# STM32F303 register map
File version: 1.9
CPU: CM4 r1p0, little endian, MPU, FPU, 3 interrupt priority bits
Registers are 32-bit, read-write, reset 0x0 unless marked. A register's access mark holds for its fields unless they carry their own. Offsets are from the block's base; [hi:lo] are bit positions; {n}, {i} and the like mark numbered series.

## SYSCFG_COMP_OPAMP — System configuration controller _Comparator and Operational amplifier
Base 0x40010000
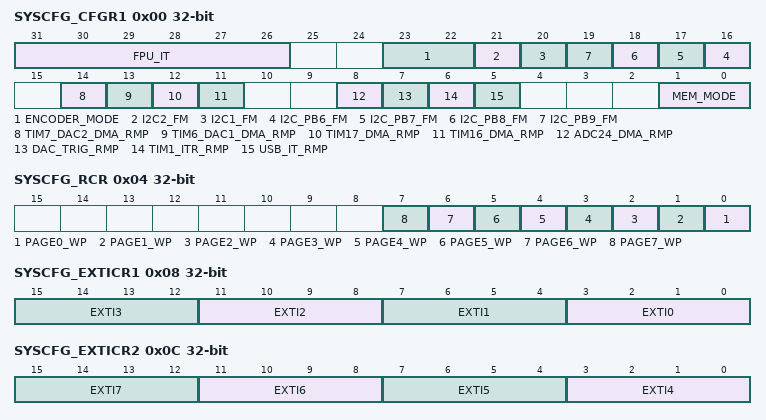
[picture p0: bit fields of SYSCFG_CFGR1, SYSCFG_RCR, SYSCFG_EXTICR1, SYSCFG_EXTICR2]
0x00 SYSCFG_CFGR1 — configuration register 1
  [31:26] FPU_IT — Interrupt enable bits from FPU
  [23:22] ENCODER_MODE
  [21] I2C2_FM — I2C2 Fast Mode Plus
  [20] I2C1_FM — I2C1 Fast Mode Plus
  [n+10] I2C_PB{n}_FM (n=6..9) — Fast Mode Plus (FM+) driving capability activation bits.
  [14] TIM7_DAC2_DMA_RMP — TIM7 and DAC2 DMA request remapping bit
  [13] TIM6_DAC1_DMA_RMP — TIM6 and DAC1 DMA request remapping bit
  [12] TIM17_DMA_RMP — TIM17 DMA request remapping bit
  [11] TIM16_DMA_RMP — TIM16 DMA request remapping bit
  [8] ADC24_DMA_RMP — ADC24 DMA remapping bit
  [7] DAC_TRIG_RMP — DAC trigger remap (when TSEL = 001)
  [6] TIM1_ITR_RMP — Timer 1 ITR3 selection
  [5] USB_IT_RMP — USB interrupt remap
  [1:0] MEM_MODE — Memory mapping selection bits
0x04 SYSCFG_RCR — CCM SRAM protection register
  [n] PAGE{n}_WP (n=0..7) — CCM SRAM page write protection bit
0x08 SYSCFG_EXTICR1 — external interrupt configuration register 1
  [4n+3:4n] EXTI{n} (n=0..3) — EXTI {n} configuration bits
0x0C SYSCFG_EXTICR2 — external interrupt configuration register 2
  [4n-13:4n-16] EXTI{n} (n=4..7) — EXTI {n} configuration bits
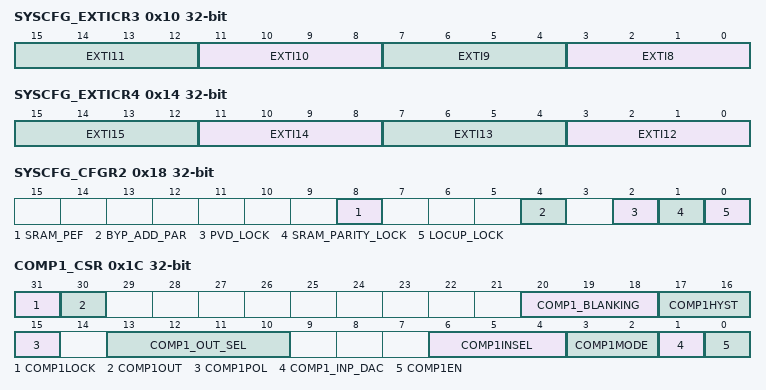
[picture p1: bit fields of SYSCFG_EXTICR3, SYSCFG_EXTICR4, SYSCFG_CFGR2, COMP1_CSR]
0x10 SYSCFG_EXTICR3 — external interrupt configuration register 3
  [4n-29:4n-32] EXTI{n} (n=8..11) — EXTI {n} configuration bits
0x14 SYSCFG_EXTICR4 — external interrupt configuration register 4
  [4n-45:4n-48] EXTI{n} (n=12..15) — EXTI {n} configuration bits
0x18 SYSCFG_CFGR2 — configuration register 2
  [8] SRAM_PEF — SRAM parity flag
  [4] BYP_ADD_PAR — Bypass address bit 29 in parity calculation
  [2] PVD_LOCK — PVD lock enable bit
  [1] SRAM_PARITY_LOCK — SRAM parity lock bit
  [0] LOCUP_LOCK — Cortex-M0 LOCKUP bit enable bit
0x1C COMP1_CSR access per field — control and status register
  [31] COMP1LOCK rw — Comparator 1 lock
  [30] COMP1OUT ro — Comparator 1 output
  [20:18] COMP1_BLANKING rw — Comparator 1 blanking source
  [17:16] COMP1HYST rw — Comparator 1 hysteresis
  [15] COMP1POL rw — Comparator 1 output polarity
  [13:10] COMP1_OUT_SEL rw — Comparator 1 output selection
  [6:4] COMP1INSEL rw — Comparator 1 inverting input selection
  [3:2] COMP1MODE rw — Comparator 1 mode
  [1] COMP1_INP_DAC rw
  [0] COMP1EN rw — Comparator 1 enable
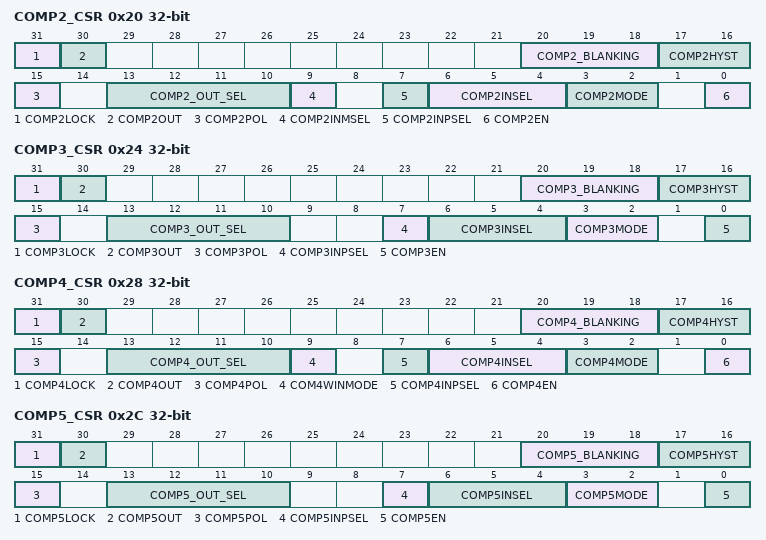
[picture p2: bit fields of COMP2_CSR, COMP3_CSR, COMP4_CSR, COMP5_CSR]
0x20 COMP2_CSR — control and status register
  [31] COMP2LOCK — Comparator 2 lock
  [30] COMP2OUT — Comparator 2 output
  [20:18] COMP2_BLANKING — Comparator 2 blanking source
  [17:16] COMP2HYST — Comparator 2 hysteresis
  [15] COMP2POL — Comparator 2 output polarity
  [13:10] COMP2_OUT_SEL — Comparator 2 output selection
  [9] COMP2INMSEL — Comparator 1inverting input selection
  [7] COMP2INPSEL — Comparator 2 non inverted input selection
  [6:4] COMP2INSEL — Comparator 2 inverting input selection
  [3:2] COMP2MODE — Comparator 2 mode
  [0] COMP2EN — Comparator 2 enable
0x24 COMP3_CSR access per field — control and status register
  [31] COMP3LOCK rw — Comparator 3 lock
  [30] COMP3OUT ro — Comparator 3 output
  [20:18] COMP3_BLANKING rw — Comparator 3 blanking source
  [17:16] COMP3HYST rw — Comparator 3 hysteresis
  [15] COMP3POL rw — Comparator 3 output polarity
  [13:10] COMP3_OUT_SEL rw — Comparator 3 output selection
  [7] COMP3INPSEL rw — Comparator 3 non inverted input selection
  [6:4] COMP3INSEL rw — Comparator 3 inverting input selection
  [3:2] COMP3MODE rw — Comparator 3 mode
  [0] COMP3EN rw — Comparator 3 enable
0x28 COMP4_CSR access per field — control and status register
  [31] COMP4LOCK rw — Comparator 4 lock
  [30] COMP4OUT ro — Comparator 4 output
  [20:18] COMP4_BLANKING rw — Comparator 4 blanking source
  [17:16] COMP4HYST rw — Comparator 4 hysteresis
  [15] COMP4POL rw — Comparator 4 output polarity
  [13:10] COMP4_OUT_SEL rw — Comparator 4 output selection
  [9] COM4WINMODE rw — Comparator 4 window mode
  [7] COMP4INPSEL rw — Comparator 4 non inverted input selection
  [6:4] COMP4INSEL rw — Comparator 4 inverting input selection
  [3:2] COMP4MODE rw — Comparator 4 mode
  [0] COMP4EN rw — Comparator 4 enable
0x2C COMP5_CSR access per field — control and status register
  [31] COMP5LOCK rw — Comparator 5 lock
  [30] COMP5OUT ro — Comparator51 output
  [20:18] COMP5_BLANKING rw — Comparator 5 blanking source
  [17:16] COMP5HYST rw — Comparator 5 hysteresis
  [15] COMP5POL rw — Comparator 5 output polarity
  [13:10] COMP5_OUT_SEL rw — Comparator 5 output selection
  [7] COMP5INPSEL rw — Comparator 5 non inverted input selection
  [6:4] COMP5INSEL rw — Comparator 5 inverting input selection
  [3:2] COMP5MODE rw — Comparator 5 mode
  [0] COMP5EN rw — Comparator 5 enable
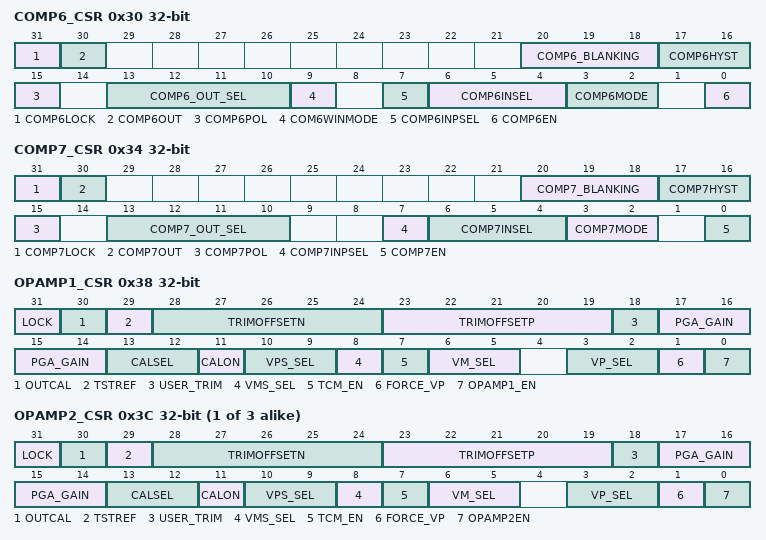
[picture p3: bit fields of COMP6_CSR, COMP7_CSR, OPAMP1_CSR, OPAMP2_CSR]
0x30 COMP6_CSR access per field — control and status register
  [31] COMP6LOCK rw — Comparator 6 lock
  [30] COMP6OUT ro — Comparator 6 output
  [20:18] COMP6_BLANKING rw — Comparator 6 blanking source
  [17:16] COMP6HYST rw — Comparator 6 hysteresis
  [15] COMP6POL rw — Comparator 6 output polarity
  [13:10] COMP6_OUT_SEL rw — Comparator 6 output selection
  [9] COM6WINMODE rw — Comparator 6 window mode
  [7] COMP6INPSEL rw — Comparator 6 non inverted input selection
  [6:4] COMP6INSEL rw — Comparator 6 inverting input selection
  [3:2] COMP6MODE rw — Comparator 6 mode
  [0] COMP6EN rw — Comparator 6 enable
0x34 COMP7_CSR access per field — control and status register
  [31] COMP7LOCK rw — Comparator 7 lock
  [30] COMP7OUT ro — Comparator 7 output
  [20:18] COMP7_BLANKING rw — Comparator 7 blanking source
  [17:16] COMP7HYST rw — Comparator 7 hysteresis
  [15] COMP7POL rw — Comparator 7 output polarity
  [13:10] COMP7_OUT_SEL rw — Comparator 7 output selection
  [7] COMP7INPSEL rw — Comparator 7 non inverted input selection
  [6:4] COMP7INSEL rw — Comparator 7 inverting input selection
  [3:2] COMP7MODE rw — Comparator 7 mode
  [0] COMP7EN rw — Comparator 7 enable
0x38 OPAMP1_CSR access per field — control register
  [31] LOCK rw — OPAMP 1 lock
  [30] OUTCAL ro — OPAMP 1 ouput status flag
  [29] TSTREF rw
  [28:24] TRIMOFFSETN rw — Offset trimming value (NMOS)
  [23:19] TRIMOFFSETP rw — Offset trimming value (PMOS)
  [18] USER_TRIM rw — User trimming enable
  [17:14] PGA_GAIN rw — Gain in PGA mode
  [13:12] CALSEL rw — Calibration selection
  [11] CALON rw — Calibration mode enable
  [10:9] VPS_SEL rw — OPAMP1 Non inverting input secondary selection
  [8] VMS_SEL rw — OPAMP1 inverting input secondary selection
  [7] TCM_EN rw — Timer controlled Mux mode enable
  [6:5] VM_SEL rw — OPAMP1 inverting input selection
  [3:2] VP_SEL rw — OPAMP1 Non inverting input selection
  [1] FORCE_VP rw
  [0] OPAMP1_EN rw — OPAMP1 enable
{0x34+4i} OPAMP{i}_CSR access per field (i=2..4) — control register
  [31] LOCK rw — OPAMP {i} lock
  [30] OUTCAL ro — OPAMP {i} ouput status flag
  [29] TSTREF rw
  [28:24] TRIMOFFSETN rw — Offset trimming value (NMOS)
  [23:19] TRIMOFFSETP rw — Offset trimming value (PMOS)
  [18] USER_TRIM rw — User trimming enable
  [17:14] PGA_GAIN rw — Gain in PGA mode
  [13:12] CALSEL rw — Calibration selection
  [11] CALON rw — Calibration mode enable
  [10:9] VPS_SEL rw — OPAMP{i} Non inverting input secondary selection
  [8] VMS_SEL rw — OPAMP{i} inverting input secondary selection
  [7] TCM_EN rw — Timer controlled Mux mode enable
  [6:5] VM_SEL rw — OPAMP{i} inverting input selection
  [3:2] VP_SEL rw — OPAMP{i} Non inverting input selection
  [1] FORCE_VP rw
  [0] OPAMP{i}EN rw — OPAMP{i} enable
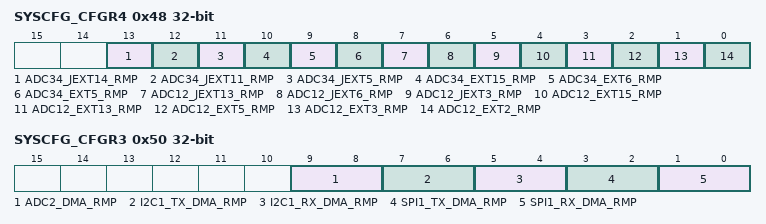
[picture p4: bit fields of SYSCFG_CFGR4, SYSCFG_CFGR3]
0x48 SYSCFG_CFGR4 — SYSCFG configuration register 4
  [13] ADC34_JEXT14_RMP — Controls the Input trigger of ADC34 injected channel JEXT14
  [12] ADC34_JEXT11_RMP — Controls the Input trigger of ADC34 injected channel JEXT11
  [11] ADC34_JEXT5_RMP — Controls the Input trigger of ADC34 injected channel JEXT5
  [10] ADC34_EXT15_RMP — Controls the Input trigger of ADC34 regular channel EXT15
  [9] ADC34_EXT6_RMP — Controls the Input trigger of ADC34 regular channel EXT6
  [8] ADC34_EXT5_RMP — Controls the Input trigger of ADC34 regular channel EXT5
  [7] ADC12_JEXT13_RMP — Controls the Input trigger of ADC12 injected channel EXTI13
  [6] ADC12_JEXT6_RMP — Controls the Input trigger of ADC12 injected channel EXTI6
  [5] ADC12_JEXT3_RMP — Controls the Input trigger of ADC12 injected channel EXTI3
  [4] ADC12_EXT15_RMP — Controls the Input trigger of ADC12 regular channel EXT15
  [3] ADC12_EXT13_RMP — Controls the Input trigger of ADC12 regular channel EXT13
  [2] ADC12_EXT5_RMP — Controls the Input trigger of ADC12 regular channel EXT5
  [1] ADC12_EXT3_RMP — Controls the Input trigger of ADC12 regular channel EXT3
  [0] ADC12_EXT2_RMP — Controls the Input trigger of ADC12 regular channel EXT2
0x50 SYSCFG_CFGR3 — SYSCFG configuration register 3
  [9:8] ADC2_DMA_RMP — ADC2 DMA channel remapping bit
  [7:6] I2C1_TX_DMA_RMP — I2C1_TX DMA remapping bit
  [5:4] I2C1_RX_DMA_RMP — I2C1_RX DMA remapping bit
  [3:2] SPI1_TX_DMA_RMP — SPI1_TX DMA remapping bit
  [1:0] SPI1_RX_DMA_RMP — SPI1_RX DMA remapping bit
